# iospear310 register map
Registers are 32-bit, access not given, no defined reset value unless marked. A register's access mark holds for its fields unless they carry their own. Addresses are absolute; registers are grouped by the start of their names; [hi:lo] are bit positions; {n}, {i} and the like mark numbered series; 'fields as' and 'values as' point back to an identical list.

## MACB2
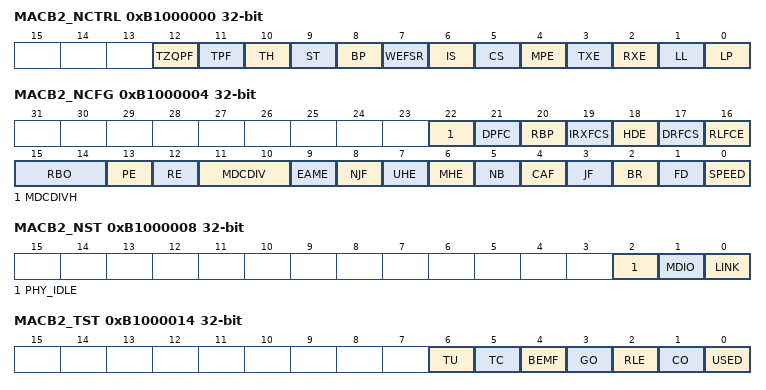
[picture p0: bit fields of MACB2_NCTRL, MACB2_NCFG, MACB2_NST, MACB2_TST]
0xB1000000 MACB2_NCTRL
  [12] TZQPF, [11] TPF, [10] TH, [9] ST, [8] BP, [7] WEFSR, [6] IS, [5] CS, [4] MPE, [3] TXE, [2] RXE, [1] LL, [0] LP
0xB1000004 MACB2_NCFG
  [22] MDCDIVH, [21] DPFC, [20] RBP, [19] IRXFCS, [18] HDE, [17] DRFCS, [16] RLFCE, [15:14] RBO, [13] PE, [12] RE, [11:10] MDCDIV, [9] EAME, [8] NJF, [7] UHE, [6] MHE, [5] NB, [4] CAF, [3] JF, [2] BR, [1] FD, [0] SPEED
0xB1000008 MACB2_NST
  [2] PHY_IDLE, [1] MDIO, [0] LINK
0xB1000014 MACB2_TST
  [6] TU, [5] TC, [4] BEMF, [3] GO, [2] RLE, [1] CO, [0] USED
0xB1000018 MACB2_RBQP
0xB100001C MACB2_TBQP
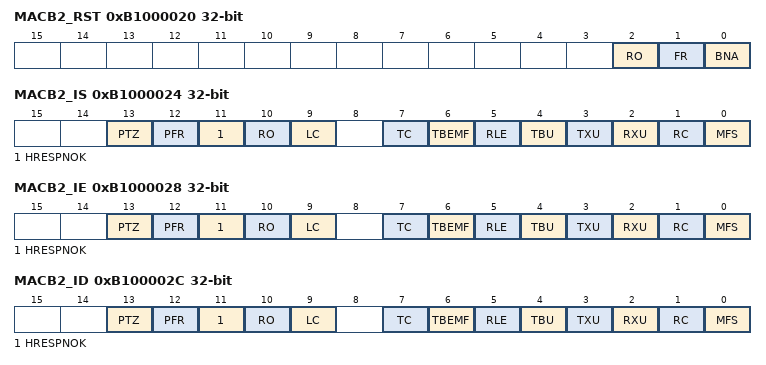
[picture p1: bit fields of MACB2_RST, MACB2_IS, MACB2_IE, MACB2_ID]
0xB1000020 MACB2_RST
  [2] RO, [1] FR, [0] BNA
0xB1000024 MACB2_IS
  [13] PTZ, [12] PFR, [11] HRESPNOK, [10] RO, [9] LC, [7] TC, [6] TBEMF, [5] RLE, [4] TBU, [3] TXU, [2] RXU, [1] RC, [0] MFS
0xB1000028 MACB2_IE
  fields as MACB2_IS
0xB100002C MACB2_ID
  fields as MACB2_IS
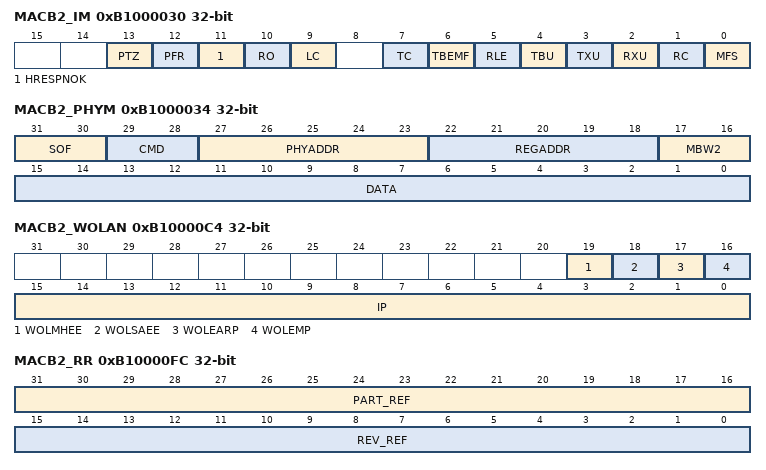
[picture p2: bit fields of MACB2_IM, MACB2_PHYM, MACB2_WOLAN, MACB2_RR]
0xB1000030 MACB2_IM
  fields as MACB2_IS
0xB1000034 MACB2_PHYM
  [31:30] SOF, [29:28] CMD, [27:23] PHYADDR, [22:18] REGADDR, [17:16] MBW2, [15:0] DATA
0xB1000038 MACB2_PT
  [15:0] PT
0xB100003C MACB2_PFR
  [15:0] FRAME_CNTR
0xB1000040 MACB2_FT
  [15:0] FRAME_CNTR
0xB1000044 MACB2_SCF
  [15:0] FRAME_CNTR
0xB1000048 MACB2_MCF
  [15:0] FRAME_CNTR
0xB100004C MACB2_FR
  [23:0] FRAME_CNTR
0xB1000050 MACB2_FCSE
  [7:0] FCSE
0xB1000054 MACB2_AE
  [7:0] AE
0xB1000058 MACB2_DTF
  [15:0] DTF
0xB100005C MACB2_LC
  [7:0] LC
0xB1000060 MACB2_EC
  [7:0] EC
0xB1000064 MACB2_TUE
  [7:0] TUE
0xB1000068 MACB2_CSE
  [7:0] CSE
0xB100006C MACB2_RRE
  [15:0] RRE
0xB1000070 MACB2_ROE
  [7:0] ROE
0xB1000074 MACB2_RSE
  [7:0] REE
0xB1000078 MACB2_ELE
  [7:0] ELE
0xB100007C MACB2_RJ
  [7:0] RJ
0xB1000080 MACB2_UF
  [7:0] UF
0xB1000084 MACB2_SEQTE
  [7:0] SQETE
0xB1000088 MACB2_RLFM
  [7:0] RLFM
0xB100008C MACB2_TPF
  [15:0] TPF
0xB1000090 MACB2_HRB
0xB1000094 MACB2_HRT
{0xB1000090+8i} MACB2_SAB{i} (i=1..4)
{0xB1000094+8i} MACB2_SAT{i} (i=1..4)
  [15:0] ADDR
0xB10000B8 MACB2_TIDC
  [15:0] ID
0xB10000BC MACB2_TPQ
  [15:0] TPQ
0xB10000C4 MACB2_WOLAN
  [19] WOLMHEE, [18] WOLSAEE, [17] WOLEARP, [16] WOLEMP, [15:0] IP
0xB10000FC MACB2_RR
  [31:16] PART_REF, [15:0] REV_REF

## MACB3
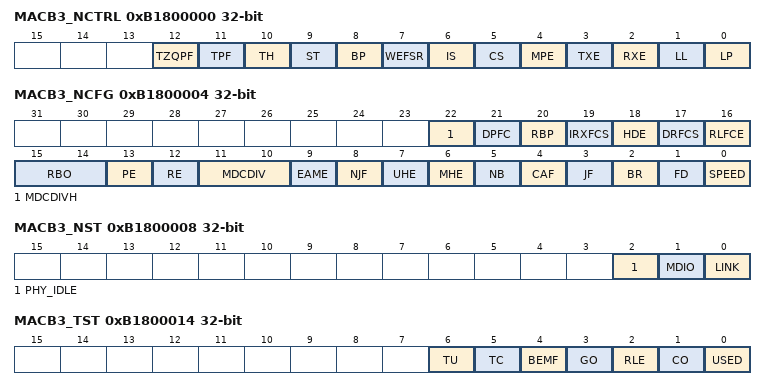
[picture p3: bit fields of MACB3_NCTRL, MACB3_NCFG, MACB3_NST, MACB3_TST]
0xB1800000 MACB3_NCTRL
  [12] TZQPF, [11] TPF, [10] TH, [9] ST, [8] BP, [7] WEFSR, [6] IS, [5] CS, [4] MPE, [3] TXE, [2] RXE, [1] LL, [0] LP
0xB1800004 MACB3_NCFG
  [22] MDCDIVH, [21] DPFC, [20] RBP, [19] IRXFCS, [18] HDE, [17] DRFCS, [16] RLFCE, [15:14] RBO, [13] PE, [12] RE, [11:10] MDCDIV, [9] EAME, [8] NJF, [7] UHE, [6] MHE, [5] NB, [4] CAF, [3] JF, [2] BR, [1] FD, [0] SPEED
0xB1800008 MACB3_NST
  [2] PHY_IDLE, [1] MDIO, [0] LINK
0xB1800014 MACB3_TST
  [6] TU, [5] TC, [4] BEMF, [3] GO, [2] RLE, [1] CO, [0] USED
0xB1800018 MACB3_RBQP
0xB180001C MACB3_TBQP
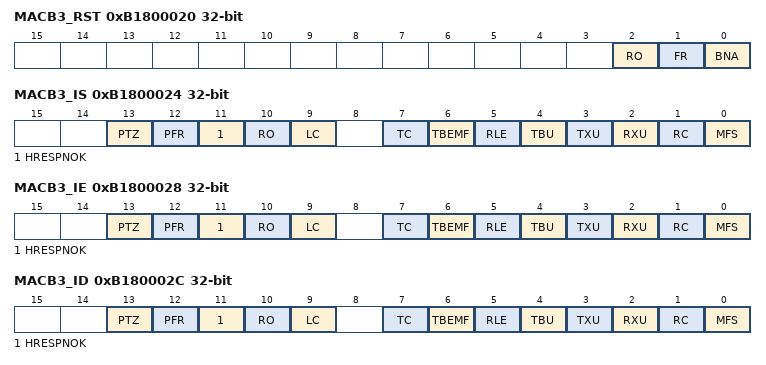
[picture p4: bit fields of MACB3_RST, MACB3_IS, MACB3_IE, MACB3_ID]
0xB1800020 MACB3_RST
  [2] RO, [1] FR, [0] BNA
0xB1800024 MACB3_IS
  [13] PTZ, [12] PFR, [11] HRESPNOK, [10] RO, [9] LC, [7] TC, [6] TBEMF, [5] RLE, [4] TBU, [3] TXU, [2] RXU, [1] RC, [0] MFS
0xB1800028 MACB3_IE
  fields as MACB3_IS
0xB180002C MACB3_ID
  fields as MACB3_IS
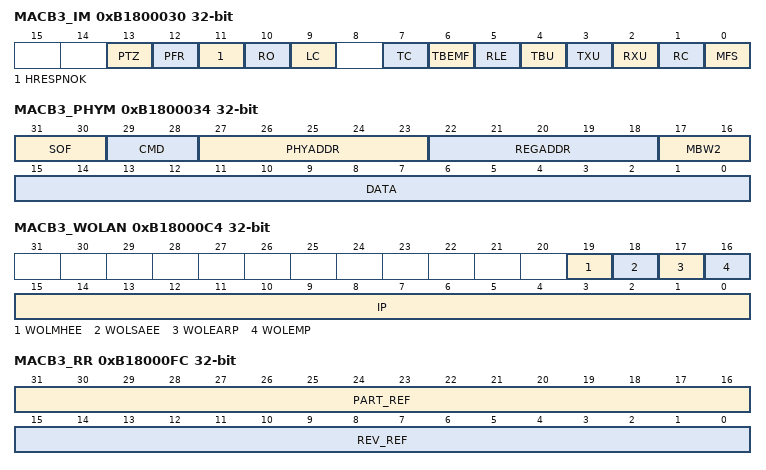
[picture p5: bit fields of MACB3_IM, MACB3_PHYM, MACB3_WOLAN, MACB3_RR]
0xB1800030 MACB3_IM
  fields as MACB3_IS
0xB1800034 MACB3_PHYM
  [31:30] SOF, [29:28] CMD, [27:23] PHYADDR, [22:18] REGADDR, [17:16] MBW2, [15:0] DATA
0xB1800038 MACB3_PT
  [15:0] PT
0xB180003C MACB3_PFR
  [15:0] FRAME_CNTR
0xB1800040 MACB3_FT
  [15:0] FRAME_CNTR
0xB1800044 MACB3_SCF
  [15:0] FRAME_CNTR
0xB1800048 MACB3_MCF
  [15:0] FRAME_CNTR
0xB180004C MACB3_FR
  [23:0] FRAME_CNTR
0xB1800050 MACB3_FCSE
  [7:0] FCSE
0xB1800054 MACB3_AE
  [7:0] AE
0xB1800058 MACB3_DTF
  [15:0] DTF
0xB180005C MACB3_LC
  [7:0] LC
0xB1800060 MACB3_EC
  [7:0] EC
0xB1800064 MACB3_TUE
  [7:0] TUE
0xB1800068 MACB3_CSE
  [7:0] CSE
0xB180006C MACB3_RRE
  [15:0] RRE
0xB1800070 MACB3_ROE
  [7:0] ROE
0xB1800074 MACB3_RSE
  [7:0] REE
0xB1800078 MACB3_ELE
  [7:0] ELE
0xB180007C MACB3_RJ
  [7:0] RJ
0xB1800080 MACB3_UF
  [7:0] UF
0xB1800084 MACB3_SEQTE
  [7:0] SQETE
0xB1800088 MACB3_RLFM
  [7:0] RLFM
0xB180008C MACB3_TPF
  [15:0] TPF
0xB1800090 MACB3_HRB
0xB1800094 MACB3_HRT
{0xB1800090+8i} MACB3_SAB{i} (i=1..4)
{0xB1800094+8i} MACB3_SAT{i} (i=1..4)
  [15:0] ADDR
0xB18000B8 MACB3_TIDC
  [15:0] ID
0xB18000BC MACB3_TPQ
  [15:0] TPQ
0xB18000C4 MACB3_WOLAN
  [19] WOLMHEE, [18] WOLSAEE, [17] WOLEARP, [16] WOLEMP, [15:0] IP
0xB18000FC MACB3_RR
  [31:16] PART_REF, [15:0] REV_REF

## GenMemCtrl
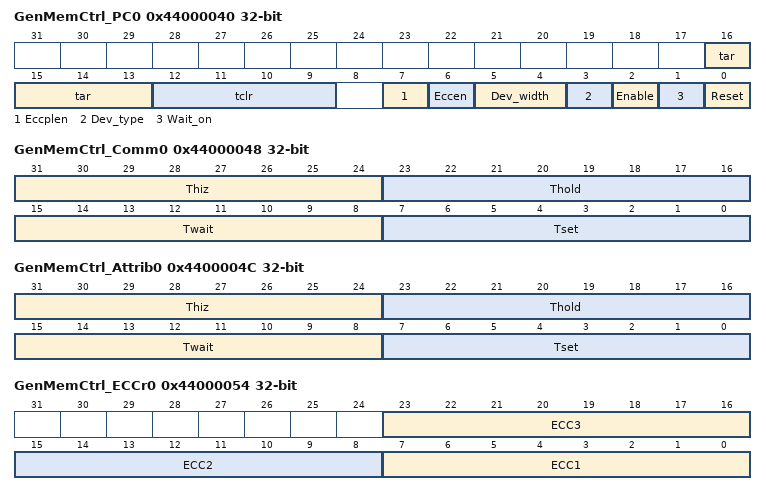
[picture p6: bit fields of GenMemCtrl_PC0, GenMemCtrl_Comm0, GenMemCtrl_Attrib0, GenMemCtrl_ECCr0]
0x44000040 GenMemCtrl_PC0
  [16:13] tar, [12:9] tclr, [7] Eccplen, [6] Eccen, [5:4] Dev_width, [3] Dev_type, [2] Enable, [1] Wait_on, [0] Reset
0x44000048 GenMemCtrl_Comm0
  [31:24] Thiz, [23:16] Thold, [15:8] Twait, [7:0] Tset
0x4400004C GenMemCtrl_Attrib0
  [31:24] Thiz, [23:16] Thold, [15:8] Twait, [7:0] Tset
0x44000054 GenMemCtrl_ECCr0
  [23:16] ECC3, [15:8] ECC2, [7:0] ECC1
{0x44000FE0+4i} GenMemCtrl_PeriphID{i} (i=0..3)
{0x44000FF0+4i} GenMemCtrl_PCellID{i} (i=0..3)

## HDLC1
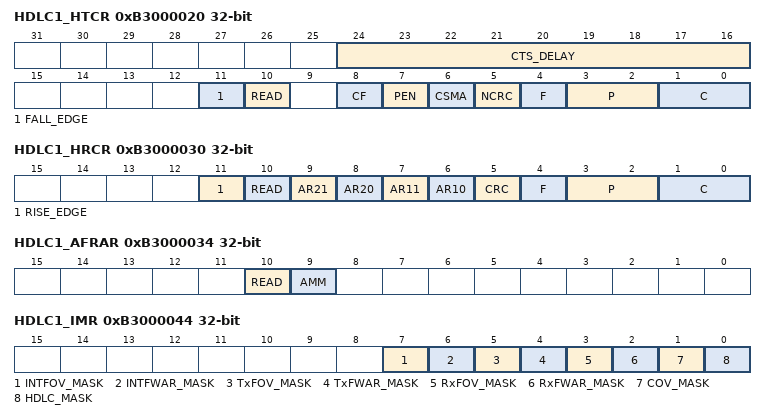
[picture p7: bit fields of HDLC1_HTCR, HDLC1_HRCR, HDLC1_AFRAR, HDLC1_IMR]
0xB3000020 HDLC1_HTCR
  [24:16] CTS_DELAY, [11] FALL_EDGE, [10] READ, [8] CF, [7] PEN, [6] CSMA, [5] NCRC, [4] F, [3:2] P, [1:0] C
0xB3000030 HDLC1_HRCR
  [11] RISE_EDGE, [10] READ, [9] AR21, [8] AR20, [7] AR11, [6] AR10, [5] CRC, [4] F, [3:2] P, [1:0] C
0xB3000034 HDLC1_AFRAR
  [10] READ, [9] AMM
0xB3000038 HDLC1_AFRDR 16-bit
0xB3000040 HDLC1_IBAR
0xB3000044 HDLC1_IMR
  [7] INTFOV_MASK, [6] INTFWAR_MASK, [5] TxFOV_MASK, [4] TxFWAR_MASK, [3] RxFOV_MASK, [2] RxFWAR_MASK, [1] COV_MASK, [0] HDLC_MASK
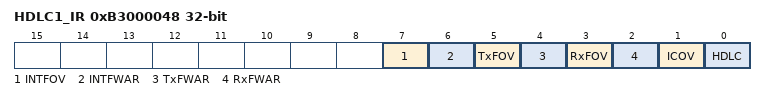
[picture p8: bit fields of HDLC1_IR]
0xB3000048 HDLC1_IR
  [7] INTFOV, [6] INTFWAR, [5] TxFOV, [4] TxFWAR, [3] RxFOV, [2] RxFWAR, [1] ICOV, [0] HDLC
0xB300004C HDLC1_IQSR
  [1:0] HS

## HDLC2
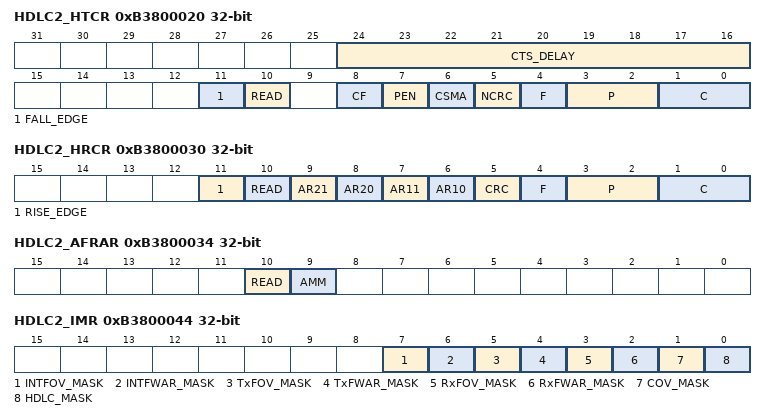
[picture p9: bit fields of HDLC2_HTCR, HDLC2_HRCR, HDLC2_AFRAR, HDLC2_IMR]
0xB3800020 HDLC2_HTCR
  [24:16] CTS_DELAY, [11] FALL_EDGE, [10] READ, [8] CF, [7] PEN, [6] CSMA, [5] NCRC, [4] F, [3:2] P, [1:0] C
0xB3800030 HDLC2_HRCR
  [11] RISE_EDGE, [10] READ, [9] AR21, [8] AR20, [7] AR11, [6] AR10, [5] CRC, [4] F, [3:2] P, [1:0] C
0xB3800034 HDLC2_AFRAR
  [10] READ, [9] AMM
0xB3800038 HDLC2_AFRDR 16-bit
0xB3800040 HDLC2_IBAR
0xB3800044 HDLC2_IMR
  [7] INTFOV_MASK, [6] INTFWAR_MASK, [5] TxFOV_MASK, [4] TxFWAR_MASK, [3] RxFOV_MASK, [2] RxFWAR_MASK, [1] COV_MASK, [0] HDLC_MASK
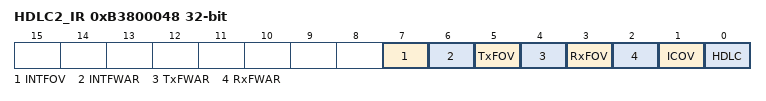
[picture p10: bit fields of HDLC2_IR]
0xB3800048 HDLC2_IR
  [7] INTFOV, [6] INTFWAR, [5] TxFOV, [4] TxFWAR, [3] RxFOV, [2] RxFWAR, [1] ICOV, [0] HDLC
0xB380004C HDLC2_IQSR
  [1:0] HS

## TDM
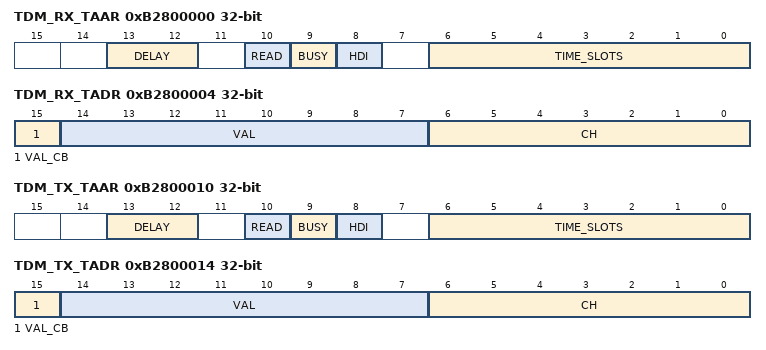
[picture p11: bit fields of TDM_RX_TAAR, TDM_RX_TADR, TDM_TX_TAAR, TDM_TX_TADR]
0xB2800000 TDM_RX_TAAR
  [13:12] DELAY, [10] READ, [9] BUSY, [8] HDI, [6:0] TIME_SLOTS
0xB2800004 TDM_RX_TADR
  [15] VAL_CB, [14:7] VAL, [6:0] CH
0xB2800010 TDM_TX_TAAR
  [13:12] DELAY, [10] READ, [9] BUSY, [8] HDI, [6:0] TIME_SLOTS
0xB2800014 TDM_TX_TADR
  [15] VAL_CB, [14:7] VAL, [6:0] CH
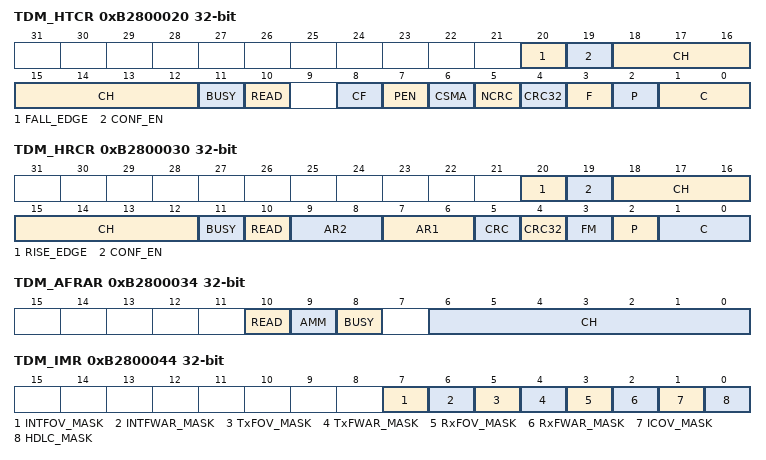
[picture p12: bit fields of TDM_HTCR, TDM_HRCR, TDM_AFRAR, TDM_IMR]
0xB2800020 TDM_HTCR
  [20] FALL_EDGE, [19] CONF_EN, [18:12] CH, [11] BUSY, [10] READ, [8] CF, [7] PEN, [6] CSMA, [5] NCRC, [4] CRC32, [3] F, [2] P, [1:0] C
0xB2800030 TDM_HRCR
  [20] RISE_EDGE, [19] CONF_EN, [18:12] CH, [11] BUSY, [10] READ, [9:8] AR2, [7:6] AR1, [5] CRC, [4] CRC32, [3] FM, [2] P, [1:0] C
0xB2800034 TDM_AFRAR
  [10] READ, [9] AMM, [8] BUSY, [6:0] CH
0xB2800038 TDM_AFRDR
0xB2800040 TDM_IBAR
0xB2800044 TDM_IMR
  [7] INTFOV_MASK, [6] INTFWAR_MASK, [5] TxFOV_MASK, [4] TxFWAR_MASK, [3] RxFOV_MASK, [2] RxFWAR_MASK, [1] ICOV_MASK, [0] HDLC_MASK
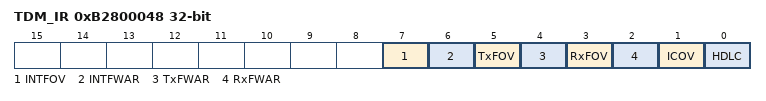
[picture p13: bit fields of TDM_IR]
0xB2800048 TDM_IR
  [7] INTFOV, [6] INTFWAR, [5] TxFOV, [4] TxFWAR, [3] RxFOV, [2] RxFWAR, [1] ICOV, [0] HDLC
0xB280004C TDM_IQSR
  [1:0] HS
